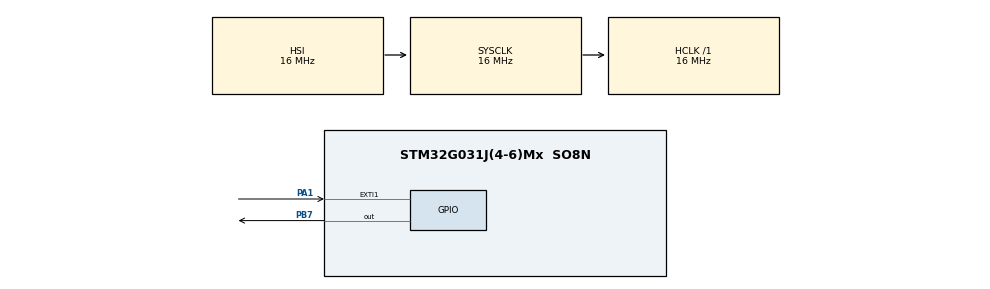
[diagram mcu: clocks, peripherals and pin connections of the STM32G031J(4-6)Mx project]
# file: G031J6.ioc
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Mcu.Family=STM32G0
Mcu.Name=STM32G031J(4-6)Mx
Mcu.Package=SO8N
NVIC.EXTI0_1_IRQn=true\:0\:0\:false\:false\:true\:true\:true
PA1.GPIO_PuPd=GPIO_PULLDOWN
PA1.Signal=GPXTI1
PA13.Mode=Serial_Wire
PA13.Signal=SYS_SWDIO
PA14-BOOT0.Mode=Serial_Wire
PA14-BOOT0.Signal=SYS_SWCLK
PB7.Signal=GPIO_Output
ProjectManager.HeapSize=0x200
ProjectManager.StackSize=0x400
ProjectManager.TargetToolchain=MDK-ARM V5.32
RCC.ADCFreq_Value=16000000
RCC.AHBFreq_Value=16000000
RCC.CortexFreq_Value=16000000
RCC.EXTERNAL_CLOCK_VALUE=12288000
RCC.HCLKFreq_Value=16000000
RCC.HSE_VALUE=8000000
RCC.HSI_VALUE=16000000
RCC.LSE_VALUE=32768
RCC.SYSCLKFreq_VALUE=16000000
RCC.VCOOutputFreq_Value=128000000
VP_SYS_VS_PIN1REMAP.Mode=PIN1REMAP
VP_SYS_VS_PIN4REMAP.Mode=PIN4REMAP
board=custom

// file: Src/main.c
/* USER CODE BEGIN Header */
/**
  ******************************************************************************
  * @file           : main.c
  * @brief          : Main program body
  ******************************************************************************
  * @attention
  *
  * <h2><center>&copy; Copyright (c) 2020 STMicroelectronics.
  * All rights reserved.</center></h2>
  *
  * This software component is licensed by ST under BSD 3-Clause license,
  * the "License"; You may not use this file except in compliance with the
  * License. You may obtain a copy of the License at:
  *                        opensource.org/licenses/BSD-3-Clause
  *
  ******************************************************************************
  */
/* USER CODE END Header */

#include "main.h"
#include "gpio.h"

void SystemClock_Config(void);

int main(void)
{

  /* MCU Configuration--------------------------------------------------------*/

  /* Reset of all peripherals, Initializes the Flash interface and the Systick. */
  HAL_Init();

  /* Configure the system clock */
  SystemClock_Config();

  /* Initialize all configured peripherals */
  MX_GPIO_Init();
  /* USER CODE BEGIN 2 */
__HAL_RCC_PWR_CLK_ENABLE();

  /* Check if the system was resumed from Standby mode */
    if (__HAL_PWR_GET_FLAG(PWR_FLAG_SB) != RESET)
    {
        /* Clear Standby flag */
        __HAL_PWR_CLEAR_FLAG(PWR_FLAG_SB);

        /* Check and Clear the Wakeup flag */
        if (__HAL_PWR_GET_FLAG(PWR_FLAG_WUF2) != RESET)
        {
        __HAL_PWR_CLEAR_FLAG(PWR_FLAG_WUF2);
        }

        /* Wait that user release the User push-button */

    }

  /* Insert 5 seconds delay */
//    HAL_Delay(2000);
	for(int i=0;i<50;i++)
	{
        HAL_GPIO_TogglePin(GPIOB, GPIO_PIN_7);
        HAL_Delay(100);
	}

  /* The Following Wakeup sequence is highly recommended prior to Standby mode entry
     - Enable wakeup
     - Clear wake up pin flag depending in edge detection & pin level.
     - Enter the Standby mode.
  */

  /* Enable WakeUp Pin PWR_WAKEUP_PIN1 connected to PA.0 */
  HAL_PWR_EnableWakeUpPin(PWR_WAKEUP_PIN1_HIGH);

  /* Clear all related wakeup flags*/
  __HAL_PWR_CLEAR_FLAG(PWR_FLAG_WUF1);

  /* Enter the Standby mode */
  HAL_PWR_EnterSTANDBYMode();
  /* USER CODE END 2 */

  /* Infinite loop */
  while (1)
  {

  }
}

void SystemClock_Config(void)
{
  RCC_OscInitTypeDef RCC_OscInitStruct = {0};
  RCC_ClkInitTypeDef RCC_ClkInitStruct = {0};

  /** Configure the main internal regulator output voltage
  */
  HAL_PWREx_ControlVoltageScaling(PWR_REGULATOR_VOLTAGE_SCALE1);
  /** Initializes the CPU, AHB and APB busses clocks
  */
  RCC_OscInitStruct.OscillatorType = RCC_OSCILLATORTYPE_HSI;
  RCC_OscInitStruct.HSIState = RCC_HSI_ON;
  RCC_OscInitStruct.HSIDiv = RCC_HSI_DIV1;
  RCC_OscInitStruct.HSICalibrationValue = RCC_HSICALIBRATION_DEFAULT;
  RCC_OscInitStruct.PLL.PLLState = RCC_PLL_NONE;
  if (HAL_RCC_OscConfig(&RCC_OscInitStruct) != HAL_OK)
  {
    Error_Handler();
  }
  /** Initializes the CPU, AHB and APB busses clocks
  */
  RCC_ClkInitStruct.ClockType = RCC_CLOCKTYPE_HCLK|RCC_CLOCKTYPE_SYSCLK
                              |RCC_CLOCKTYPE_PCLK1;
  RCC_ClkInitStruct.SYSCLKSource = RCC_SYSCLKSOURCE_HSI;
  RCC_ClkInitStruct.AHBCLKDivider = RCC_SYSCLK_DIV1;
  RCC_ClkInitStruct.APB1CLKDivider = RCC_HCLK_DIV1;

  if (HAL_RCC_ClockConfig(&RCC_ClkInitStruct, FLASH_LATENCY_0) != HAL_OK)
  {
    Error_Handler();
  }
}

void Error_Handler(void)
{
}

/************************ (C) COPYRIGHT STMicroelectronics *****END OF FILE****/
